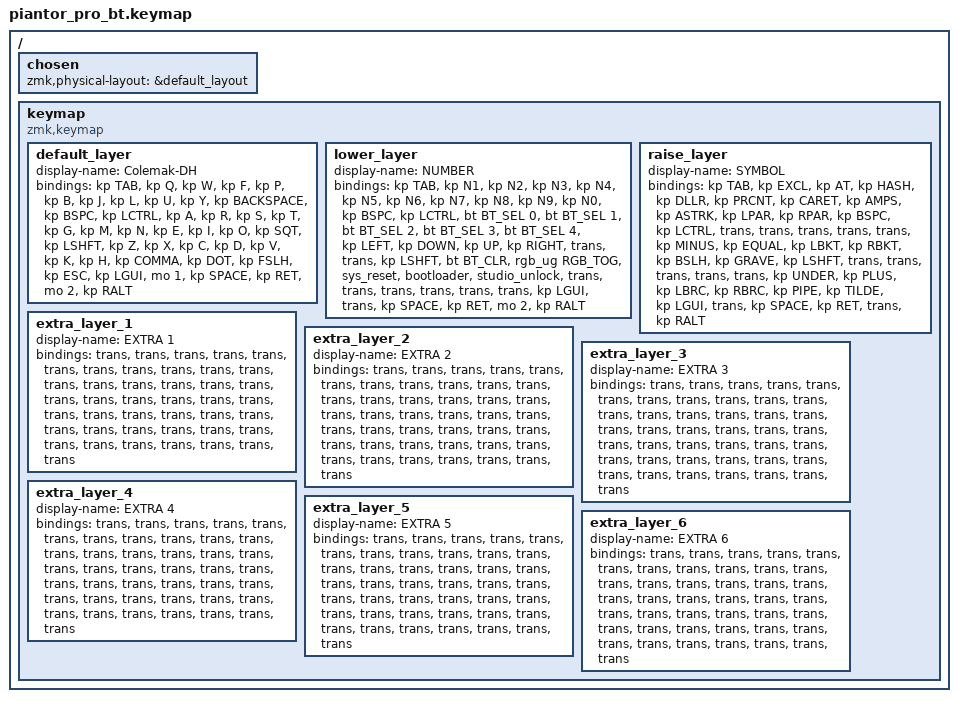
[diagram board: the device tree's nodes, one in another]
/*
 * Copyright (c) 2020 The ZMK Contributors
 *
 * SPDX-License-Identifier: MIT
 */

#include <behaviors.dtsi>
#include <dt-bindings/zmk/bt.h>
#include <dt-bindings/zmk/keys.h>
#include <dt-bindings/zmk/rgb.h>

/ {
    chosen { zmk,physical-layout = &default_layout; };
};

/ {
    keymap {
        compatible = "zmk,keymap";

        default_layer {
            display-name = "Colemak-DH";

            // --------------------------------------------------------------------------------
            // |  TAB |  Q  |  W  |  F  |  P  |  B  |  J  |  L  |  U  |  Y  |  ;  | BSPC |
            // | CTRL |  A  |  R  |  S  |  T  |  G  |  K  |  N  |  E  |  I  |  O  |  '   |
            // | SHFT |  Z  |  X  |  C  |  D  |  V  |  M  |  H  |  ,  |  .  |  /  | ESC  |
            //               | GUI | LWR | SPC | ENT | RSE | ALT |

            bindings = <
&kp TAB  &kp Q  &kp W  &kp F  &kp P  &kp B  &kp J  &kp L  &kp U  &kp Y  &kp BACKSPACE  &kp BSPC  &kp LCTRL  &kp A  &kp R  &kp S  &kp T  &kp G  &kp M  &kp N  &kp E  &kp I  &kp O  &kp SQT  &kp LSHFT  &kp Z  &kp X  &kp C  &kp D  &kp V  &kp K  &kp H  &kp COMMA  &kp DOT  &kp FSLH  &kp ESC  &kp LGUI  &mo 1  &kp SPACE  &kp RET  &mo 2  &kp RALT
            >;
        };

        lower_layer {
            display-name = "NUMBER";

            // -----------------------------------------------------------------------------------------
            // |  TAB |  1  |  2  |  3  |  4  |  5   |  6  |  7  |  8  |  9  |  0  | BSPC |
            // | CTRL | BT1 | BT2 | BT3 | BT4 | BT5   | LFT | DWN |  UP | RGT |     |      |
            // | SHFT | BTCR| RGB | RST | BOOT| Unlock|     |     |     |     |     |      |
            //               | GUI |     | SPC   | ENT |     | ALT |

            bindings = <
&kp TAB  &kp N1  &kp N2  &kp N3  &kp N4  &kp N5  &kp N6  &kp N7  &kp N8  &kp N9  &kp N0  &kp BSPC  &kp LCTRL  &bt BT_SEL 0  &bt BT_SEL 1  &bt BT_SEL 2  &bt BT_SEL 3  &bt BT_SEL 4  &kp LEFT  &kp DOWN  &kp UP  &kp RIGHT  &trans  &trans  &kp LSHFT  &bt BT_CLR  &rgb_ug RGB_TOG  &sys_reset  &bootloader  &studio_unlock  &trans  &trans  &trans  &trans  &trans  &trans  &kp LGUI  &trans  &kp SPACE  &kp RET  &mo 2  &kp RALT
            >;
        };

        raise_layer {
            display-name = "SYMBOL";

            // -----------------------------------------------------------------------------------------
            // |  TAB |  !  |  @  |  #  |  $  |  %  |  ^  |  &  |  * |  (  |  )  | BSPC |
            // | CTRL |     |     |     |     |     |  -  |  =  |  [  |  ]  |  \  |  `   |
            // | SHFT |     |     |     |     |     |  _  |  +  |  {  |  }  | "|" |  ~   |
            //               | GUI |     | SPC | ENT |     | ALT |

            bindings = <
&kp TAB  &kp EXCL  &kp AT  &kp HASH  &kp DLLR  &kp PRCNT  &kp CARET  &kp AMPS  &kp ASTRK  &kp LPAR  &kp RPAR  &kp BSPC  &kp LCTRL  &trans  &trans  &trans  &trans  &trans  &kp MINUS  &kp EQUAL  &kp LBKT  &kp RBKT  &kp BSLH  &kp GRAVE  &kp LSHFT  &trans  &trans  &trans  &trans  &trans  &kp UNDER  &kp PLUS  &kp LBRC  &kp RBRC  &kp PIPE  &kp TILDE  &kp LGUI  &trans  &kp SPACE  &kp RET  &trans  &kp RALT
            >;
        };

        // Die extra_layer Sektionen bleiben unverändert

        extra_layer_1 {
            display-name = "EXTRA 1";
            bindings = <
&trans  &trans  &trans  &trans  &trans  &trans  &trans  &trans  &trans  &trans  &trans  &trans  &trans  &trans  &trans  &trans  &trans  &trans  &trans  &trans  &trans  &trans  &trans  &trans  &trans  &trans  &trans  &trans  &trans  &trans  &trans  &trans  &trans  &trans  &trans  &trans  &trans  &trans  &trans  &trans  &trans  &trans
            >;
        };

        extra_layer_2 {
            display-name = "EXTRA 2";
            bindings = <
&trans  &trans  &trans  &trans  &trans  &trans  &trans  &trans  &trans  &trans  &trans  &trans  &trans  &trans  &trans  &trans  &trans  &trans  &trans  &trans  &trans  &trans  &trans  &trans  &trans  &trans  &trans  &trans  &trans  &trans  &trans  &trans  &trans  &trans  &trans  &trans  &trans  &trans  &trans  &trans  &trans  &trans
            >;
        };

        extra_layer_3 {
            display-name = "EXTRA 3";
            bindings = <
&trans  &trans  &trans  &trans  &trans  &trans  &trans  &trans  &trans  &trans  &trans  &trans  &trans  &trans  &trans  &trans  &trans  &trans  &trans  &trans  &trans  &trans  &trans  &trans  &trans  &trans  &trans  &trans  &trans  &trans  &trans  &trans  &trans  &trans  &trans  &trans  &trans  &trans  &trans  &trans  &trans  &trans
            >;
        };

        extra_layer_4 {
            display-name = "EXTRA 4";
            bindings = <
&trans  &trans  &trans  &trans  &trans  &trans  &trans  &trans  &trans  &trans  &trans  &trans  &trans  &trans  &trans  &trans  &trans  &trans  &trans  &trans  &trans  &trans  &trans  &trans  &trans  &trans  &trans  &trans  &trans  &trans  &trans  &trans  &trans  &trans  &trans  &trans  &trans  &trans  &trans  &trans  &trans  &trans
            >;
        };

        extra_layer_5 {
            display-name = "EXTRA 5";
            bindings = <
&trans  &trans  &trans  &trans  &trans  &trans  &trans  &trans  &trans  &trans  &trans  &trans  &trans  &trans  &trans  &trans  &trans  &trans  &trans  &trans  &trans  &trans  &trans  &trans  &trans  &trans  &trans  &trans  &trans  &trans  &trans  &trans  &trans  &trans  &trans  &trans  &trans  &trans  &trans  &trans  &trans  &trans
            >;
        };

        extra_layer_6 {
            display-name = "EXTRA 6";
            bindings = <
&trans  &trans  &trans  &trans  &trans  &trans  &trans  &trans  &trans  &trans  &trans  &trans  &trans  &trans  &trans  &trans  &trans  &trans  &trans  &trans  &trans  &trans  &trans  &trans  &trans  &trans  &trans  &trans  &trans  &trans  &trans  &trans  &trans  &trans  &trans  &trans  &trans  &trans  &trans  &trans  &trans  &trans
            >;
        };
    };
};
